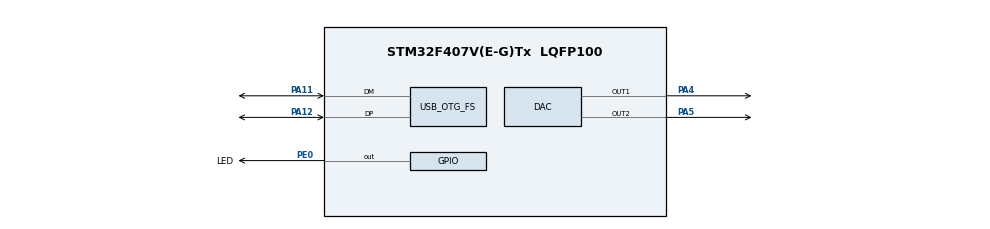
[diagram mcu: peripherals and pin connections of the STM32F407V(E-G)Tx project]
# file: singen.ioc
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DAC.DAC_OutputBuffer=DAC_OUTPUTBUFFER_DISABLE
DAC.DAC_OutputBuffer2=DAC_OUTPUTBUFFER_DISABLE
DAC.DAC_Trigger=DAC_TRIGGER_T2_TRGO
DAC.DAC_Trigger2=DAC_TRIGGER_T2_TRGO
Mcu.Family=STM32F4
Mcu.Name=STM32F407V(E-G)Tx
Mcu.Package=LQFP100
NVIC.OTG_FS_IRQn=true\:1\:0\:true\:false\:true\:false\:true
NVIC.PriorityGroup=NVIC_PRIORITYGROUP_4
NVIC.TIM2_IRQn=true\:0\:0\:false\:false\:true\:true\:true
PA11.Mode=Device_Only
PA11.Signal=USB_OTG_FS_DM
PA12.Mode=Device_Only
PA12.Signal=USB_OTG_FS_DP
PA13.Mode=Serial_Wire
PA13.Signal=SYS_JTMS-SWDIO
PA14.Mode=Serial_Wire
PA14.Signal=SYS_JTCK-SWCLK
PA4.Signal=COMP_DAC1_group
PA5.Signal=COMP_DAC2_group
PE0.GPIO_Label=LED
PE0.PinState=GPIO_PIN_RESET
PE0.Signal=GPIO_Output
PH0-OSC_IN.Mode=HSE-External-Oscillator
PH0-OSC_IN.Signal=RCC_OSC_IN
PH1-OSC_OUT.Mode=HSE-External-Oscillator
PH1-OSC_OUT.Signal=RCC_OSC_OUT
ProjectManager.HeapSize=0x200
ProjectManager.StackSize=0x400
ProjectManager.TargetToolchain=STM32CubeIDE
RCC.48MHZClocksFreq_Value=48000000
RCC.AHBFreq_Value=168000000
RCC.APB1CLKDivider=RCC_HCLK_DIV4
RCC.APB1Freq_Value=42000000
RCC.APB1TimFreq_Value=84000000
RCC.APB2CLKDivider=RCC_HCLK_DIV2
RCC.APB2Freq_Value=84000000
RCC.APB2TimFreq_Value=168000000
RCC.CortexFreq_Value=168000000
RCC.HCLKFreq_Value=168000000
RCC.HSE_VALUE=8000000
RCC.HSI_VALUE=16000000
RCC.LSE_VALUE=32768
RCC.PLLM=4
RCC.PLLN=168
RCC.PLLQ=7
RCC.SYSCLKFreq_VALUE=168000000
RCC.SYSCLKSource=RCC_SYSCLKSOURCE_PLLCLK
RCC.VCOOutputFreq_Value=336000000
SH.COMP_DAC1_group.0=DAC_OUT1,DAC_OUT1
SH.COMP_DAC2_group.0=DAC_OUT2,DAC_OUT2
STMicroelectronics.X-CUBE-ALGOBUILD.1.1.0.LibraryCcDSPOoLibraryJjDSPOoLibrary=true
TIM2.AutoReloadPreload=TIM_AUTORELOAD_PRELOAD_DISABLE
TIM2.Period=1049
TIM2.TIM_MasterOutputTrigger=TIM_TRGO_OC1
TIM2.TIM_MasterSlaveMode=TIM_MASTERSLAVEMODE_DISABLE
USB_DEVICE.CLASS_NAME_FS=CDC
USB_DEVICE.USBD_SELF_POWERED-CDC_FS=0
USB_DEVICE.VirtualMode-CDC_FS=Cdc
USB_DEVICE.VirtualModeFS=Cdc_FS
USB_OTG_FS.VirtualMode=Device_Only
VP_STMicroelectronics.X-CUBE-ALGOBUILD_VS_DSPOoLibraryJjLibrary_1.1.0.Mode=DSPOoLibraryJjLibrary
VP_TIM2_VS_ClockSourceINT.Mode=Internal
VP_USB_DEVICE_VS_USB_DEVICE_CDC_FS.Mode=CDC_FS
board=custom

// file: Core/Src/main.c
/* USER CODE BEGIN Header */
/**
  ******************************************************************************
  * @file           : main.c
  * @brief          : Main program body
  ******************************************************************************
  * @attention
  *
  * <h2><center>&copy; Copyright (c) 2021 STMicroelectronics.
  * All rights reserved.</center></h2>
  *
  * This software component is licensed by ST under BSD 3-Clause license,
  * the "License"; You may not use this file except in compliance with the
  * License. You may obtain a copy of the License at:
  *                        opensource.org/licenses/BSD-3-Clause
  *
  ******************************************************************************
  */
/* USER CODE END Header */
#include "main.h"
#include "usb_device.h"

void SystemClock_Config(void);
static void MX_GPIO_Init(void);
static void MX_DAC_Init(void);
static void MX_TIM2_Init(void);

int main(void)
{

  /* MCU Configuration--------------------------------------------------------*/

  /* Reset of all peripherals, Initializes the Flash interface and the Systick. */
  HAL_Init();

  /* Configure the system clock */
  SystemClock_Config();

  /* Initialize all configured peripherals */
  MX_GPIO_Init();
  MX_DAC_Init();
  MX_USB_DEVICE_Init();
  MX_TIM2_Init();
  /* USER CODE BEGIN 2 */

  LL_TIM_EnableIT_UPDATE(TIM2);
  LL_TIM_EnableCounter(TIM2);
  /* USER CODE END 2 */

  /* Infinite loop */
  /* USER CODE BEGIN WHILE */
  while (1)
  {
	  LL_GPIO_SetOutputPin(LED_GPIO_Port,LED_Pin);

//	  angle_offset+=0x7fff/360/10;
//	  HAL_Delay(5);
;
    /* USER CODE END WHILE */

  }
}

void SystemClock_Config(void)
{
  LL_FLASH_SetLatency(LL_FLASH_LATENCY_5);
  while(LL_FLASH_GetLatency()!= LL_FLASH_LATENCY_5)
  {
  }
  LL_PWR_SetRegulVoltageScaling(LL_PWR_REGU_VOLTAGE_SCALE1);
  LL_RCC_HSE_Enable();

   /* Wait till HSE is ready */
  while(LL_RCC_HSE_IsReady() != 1)
  {

  }
  LL_RCC_PLL_ConfigDomain_SYS(LL_RCC_PLLSOURCE_HSE, LL_RCC_PLLM_DIV_4, 168, LL_RCC_PLLP_DIV_2);
  LL_RCC_PLL_ConfigDomain_48M(LL_RCC_PLLSOURCE_HSE, LL_RCC_PLLM_DIV_4, 168, LL_RCC_PLLQ_DIV_7);
  LL_RCC_PLL_Enable();

   /* Wait till PLL is ready */
  while(LL_RCC_PLL_IsReady() != 1)
  {

  }
  LL_RCC_SetAHBPrescaler(LL_RCC_SYSCLK_DIV_1);
  LL_RCC_SetAPB1Prescaler(LL_RCC_APB1_DIV_4);
  LL_RCC_SetAPB2Prescaler(LL_RCC_APB2_DIV_2);
  LL_RCC_SetSysClkSource(LL_RCC_SYS_CLKSOURCE_PLL);

   /* Wait till System clock is ready */
  while(LL_RCC_GetSysClkSource() != LL_RCC_SYS_CLKSOURCE_STATUS_PLL)
  {

  }
  LL_SetSystemCoreClock(168000000);

   /* Update the time base */
  if (HAL_InitTick (TICK_INT_PRIORITY) != HAL_OK)
  {
    Error_Handler();
  }
}

static void MX_DAC_Init(void)
{

  LL_DAC_InitTypeDef DAC_InitStruct = {0};

  LL_GPIO_InitTypeDef GPIO_InitStruct = {0};

  /* Peripheral clock enable */
  LL_APB1_GRP1_EnableClock(LL_APB1_GRP1_PERIPH_DAC1);

  LL_AHB1_GRP1_EnableClock(LL_AHB1_GRP1_PERIPH_GPIOA);
  /**DAC GPIO Configuration
  PA4   ------> DAC_OUT1
  PA5   ------> DAC_OUT2
  */
  GPIO_InitStruct.Pin = LL_GPIO_PIN_4|LL_GPIO_PIN_5;
  GPIO_InitStruct.Mode = LL_GPIO_MODE_ANALOG;
  GPIO_InitStruct.Pull = LL_GPIO_PULL_NO;
  LL_GPIO_Init(GPIOA, &GPIO_InitStruct);

  /** DAC channel OUT1 config
  */
  DAC_InitStruct.TriggerSource = LL_DAC_TRIG_EXT_TIM2_TRGO;
  DAC_InitStruct.WaveAutoGeneration = LL_DAC_WAVE_AUTO_GENERATION_NONE;
  DAC_InitStruct.OutputBuffer = LL_DAC_OUTPUT_BUFFER_DISABLE;
  LL_DAC_Init(DAC, LL_DAC_CHANNEL_1, &DAC_InitStruct);
  /** DAC channel OUT2 config
  */
  LL_DAC_Init(DAC, LL_DAC_CHANNEL_2, &DAC_InitStruct);
  /* USER CODE BEGIN DAC_Init 2 */

  LL_DAC_EnableTrigger(DAC, LL_DAC_CHANNEL_1);
  LL_DAC_EnableTrigger(DAC, LL_DAC_CHANNEL_2);

  LL_DAC_Enable(DAC, LL_DAC_CHANNEL_1);
  LL_DAC_Enable(DAC, LL_DAC_CHANNEL_2);

  /* USER CODE END DAC_Init 2 */

}

static void MX_TIM2_Init(void)
{

  LL_TIM_InitTypeDef TIM_InitStruct = {0};

  /* Peripheral clock enable */
  LL_APB1_GRP1_EnableClock(LL_APB1_GRP1_PERIPH_TIM2);

  /* TIM2 interrupt Init */
  NVIC_SetPriority(TIM2_IRQn, NVIC_EncodePriority(NVIC_GetPriorityGrouping(),0, 0));
  NVIC_EnableIRQ(TIM2_IRQn);

  TIM_InitStruct.Prescaler = 0;
  TIM_InitStruct.CounterMode = LL_TIM_COUNTERMODE_UP;
  TIM_InitStruct.Autoreload = 167;
  TIM_InitStruct.ClockDivision = LL_TIM_CLOCKDIVISION_DIV1;
  LL_TIM_Init(TIM2, &TIM_InitStruct);
  LL_TIM_DisableARRPreload(TIM2);
  LL_TIM_SetClockSource(TIM2, LL_TIM_CLOCKSOURCE_INTERNAL);
  LL_TIM_SetTriggerOutput(TIM2, LL_TIM_TRGO_CC1IF);
  LL_TIM_DisableMasterSlaveMode(TIM2);

}

static void MX_GPIO_Init(void)
{
  LL_GPIO_InitTypeDef GPIO_InitStruct = {0};

  /* GPIO Ports Clock Enable */
  LL_AHB1_GRP1_EnableClock(LL_AHB1_GRP1_PERIPH_GPIOH);
  LL_AHB1_GRP1_EnableClock(LL_AHB1_GRP1_PERIPH_GPIOA);
  LL_AHB1_GRP1_EnableClock(LL_AHB1_GRP1_PERIPH_GPIOE);

  /**/
  LL_GPIO_ResetOutputPin(LED_GPIO_Port, LED_Pin);

  /**/
  GPIO_InitStruct.Pin = LED_Pin;
  GPIO_InitStruct.Mode = LL_GPIO_MODE_OUTPUT;
  GPIO_InitStruct.Speed = LL_GPIO_SPEED_FREQ_LOW;
  GPIO_InitStruct.OutputType = LL_GPIO_OUTPUT_PUSHPULL;
  GPIO_InitStruct.Pull = LL_GPIO_PULL_NO;
  LL_GPIO_Init(LED_GPIO_Port, &GPIO_InitStruct);

}

void Error_Handler(void)
{
  __disable_irq();
  while (1)
  {
  }
}

/************************ (C) COPYRIGHT STMicroelectronics *****END OF FILE****/
